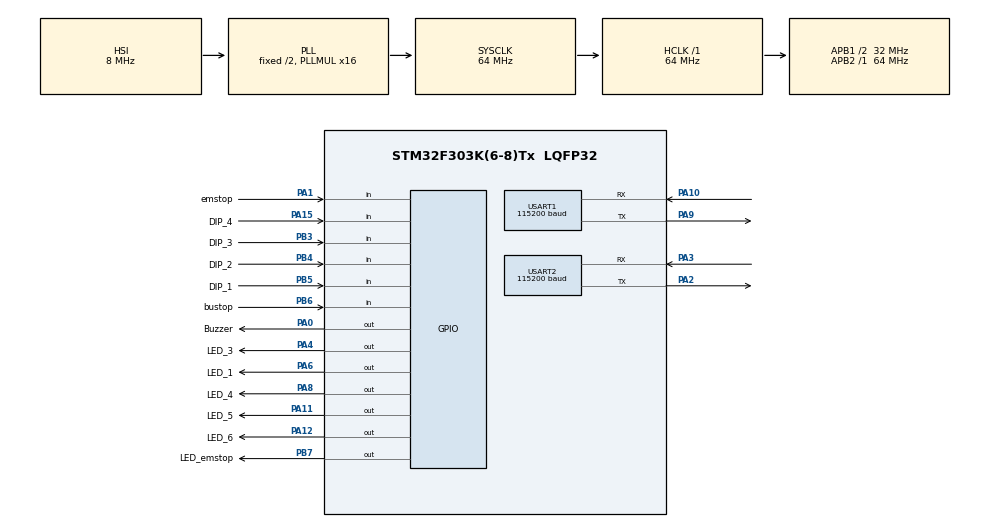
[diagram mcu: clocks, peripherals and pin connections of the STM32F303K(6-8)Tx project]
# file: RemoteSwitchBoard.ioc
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Mcu.Family=STM32F3
Mcu.Name=STM32F303K(6-8)Tx
Mcu.Package=LQFP32
NVIC.PriorityGroup=NVIC_PRIORITYGROUP_4
NVIC.USART2_IRQn=true\:0\:0\:false\:false\:true\:true\:true\:true
PA0.GPIO_Label=Buzzer
PA0.Signal=GPIO_Output
PA1.GPIO_Label=emstop
PA1.GPIO_PuPd=GPIO_PULLDOWN
PA1.Signal=GPIO_Input
PA10.Mode=Asynchronous
PA10.Signal=USART1_RX
PA11.GPIO_Label=LED_5
PA11.Signal=GPIO_Output
PA12.GPIO_Label=LED_6
PA12.Signal=GPIO_Output
PA13.Signal=SYS_JTMS-SWDIO
PA14.Signal=SYS_JTCK-SWCLK
PA15.GPIO_Label=DIP_4
PA15.GPIO_PuPd=GPIO_PULLDOWN
PA15.Signal=GPIO_Input
PA2.Mode=Asynchronous
PA2.Signal=USART2_TX
PA3.Mode=Asynchronous
PA3.Signal=USART2_RX
PA4.GPIO_Label=LED_3
PA4.Signal=GPIO_Output
PA6.GPIO_Label=LED_1
PA6.Signal=GPIO_Output
PA8.GPIO_Label=LED_4
PA8.Signal=GPIO_Output
PA9.Mode=Asynchronous
PA9.Signal=USART1_TX
PB3.GPIO_Label=DIP_3
PB3.GPIO_PuPd=GPIO_PULLDOWN
PB3.Signal=GPIO_Input
PB4.GPIO_Label=DIP_2
PB4.GPIO_PuPd=GPIO_PULLDOWN
PB4.Signal=GPIO_Input
PB5.GPIO_Label=DIP_1
PB5.GPIO_PuPd=GPIO_PULLDOWN
PB5.Signal=GPIO_Input
PB6.GPIO_Label=bustop
PB6.Signal=GPIO_Input
PB7.GPIO_Label=LED_emstop
PB7.Signal=GPIO_Output
ProjectManager.HeapSize=0x200
ProjectManager.StackSize=0x400
ProjectManager.TargetToolchain=Makefile
RCC.AHBFreq_Value=64000000
RCC.APB1CLKDivider=RCC_HCLK_DIV2
RCC.APB1Freq_Value=32000000
RCC.APB1TimFreq_Value=64000000
RCC.APB2Freq_Value=64000000
RCC.APB2TimFreq_Value=64000000
RCC.CortexFreq_Value=64000000
RCC.HCLKFreq_Value=64000000
RCC.HSE_VALUE=8000000
RCC.HSI_VALUE=8000000
RCC.PLLMUL=RCC_PLL_MUL16
RCC.SYSCLKFreq_VALUE=64000000
RCC.SYSCLKSourceVirtual=RCC_SYSCLKSOURCE_PLLCLK
USART1.BaudRate=115200
USART1.VirtualMode-Asynchronous=VM_ASYNC
USART2.BaudRate=115200
USART2.VirtualMode-Asynchronous=VM_ASYNC
board=custom

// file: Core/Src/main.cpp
/* USER CODE BEGIN Header */
/**
 ******************************************************************************
 * @file           : main.c
 * @brief          : Main program body
 ******************************************************************************
 * @attention
 *
 * Copyright (c) 2025 STMicroelectronics.
 * All rights reserved.
 *
 * This software is licensed under terms that can be found in the LICENSE file
 * in the root directory of this software component.
 * If no LICENSE file comes with this software, it is provided AS-IS.
 *
 ******************************************************************************
 */
/* USER CODE END Header */
#include "main.h"
#include "usart.h"
#include "gpio.h"

/* USER CODE BEGIN Includes */
#include "app.hpp"
#include "WioE5.hpp"
/* USER CODE END Includes */

void SystemClock_Config(void);

/* USER CODE BEGIN 0 */
App app;
WioE5 wioE5;
/* USER CODE END 0 */

int main(void)
{

  /* MCU Configuration--------------------------------------------------------*/

  /* Reset of all peripherals, Initializes the Flash interface and the Systick. */
  HAL_Init();

  /* Configure the system clock */
  SystemClock_Config();

  /* Initialize all configured peripherals */
  MX_GPIO_Init();
  MX_USART1_UART_Init();
  MX_USART2_UART_Init();
  /* USER CODE BEGIN 2 */
  HAL_Delay(1000);
  wioE5.setup();
  HAL_Delay(1000);
  app.setup();
  /* USER CODE END 2 */

  /* Infinite loop */
  while (1)
  {

    /* USER CODE BEGIN 3 */
    wioE5.loop();
    app.loop();
  }
  /* USER CODE END 3 */
}

void SystemClock_Config(void)
{
  RCC_OscInitTypeDef RCC_OscInitStruct = {0};
  RCC_ClkInitTypeDef RCC_ClkInitStruct = {0};
  RCC_PeriphCLKInitTypeDef PeriphClkInit = {0};

  /** Initializes the RCC Oscillators according to the specified parameters
   * in the RCC_OscInitTypeDef structure.
   */
  RCC_OscInitStruct.OscillatorType = RCC_OSCILLATORTYPE_HSI;
  RCC_OscInitStruct.HSIState = RCC_HSI_ON;
  RCC_OscInitStruct.HSICalibrationValue = RCC_HSICALIBRATION_DEFAULT;
  RCC_OscInitStruct.PLL.PLLState = RCC_PLL_ON;
  RCC_OscInitStruct.PLL.PLLSource = RCC_PLLSOURCE_HSI;
  RCC_OscInitStruct.PLL.PLLMUL = RCC_PLL_MUL16;
  if (HAL_RCC_OscConfig(&RCC_OscInitStruct) != HAL_OK)
  {
    Error_Handler();
  }

  /** Initializes the CPU, AHB and APB buses clocks
   */
  RCC_ClkInitStruct.ClockType = RCC_CLOCKTYPE_HCLK | RCC_CLOCKTYPE_SYSCLK | RCC_CLOCKTYPE_PCLK1 | RCC_CLOCKTYPE_PCLK2;
  RCC_ClkInitStruct.SYSCLKSource = RCC_SYSCLKSOURCE_PLLCLK;
  RCC_ClkInitStruct.AHBCLKDivider = RCC_SYSCLK_DIV1;
  RCC_ClkInitStruct.APB1CLKDivider = RCC_HCLK_DIV2;
  RCC_ClkInitStruct.APB2CLKDivider = RCC_HCLK_DIV1;

  if (HAL_RCC_ClockConfig(&RCC_ClkInitStruct, FLASH_LATENCY_2) != HAL_OK)
  {
    Error_Handler();
  }
  PeriphClkInit.PeriphClockSelection = RCC_PERIPHCLK_USART1;
  PeriphClkInit.Usart1ClockSelection = RCC_USART1CLKSOURCE_PCLK1;
  if (HAL_RCCEx_PeriphCLKConfig(&PeriphClkInit) != HAL_OK)
  {
    Error_Handler();
  }
}

void Error_Handler(void)
{
  __disable_irq();
  while (1)
  {
  }
}
